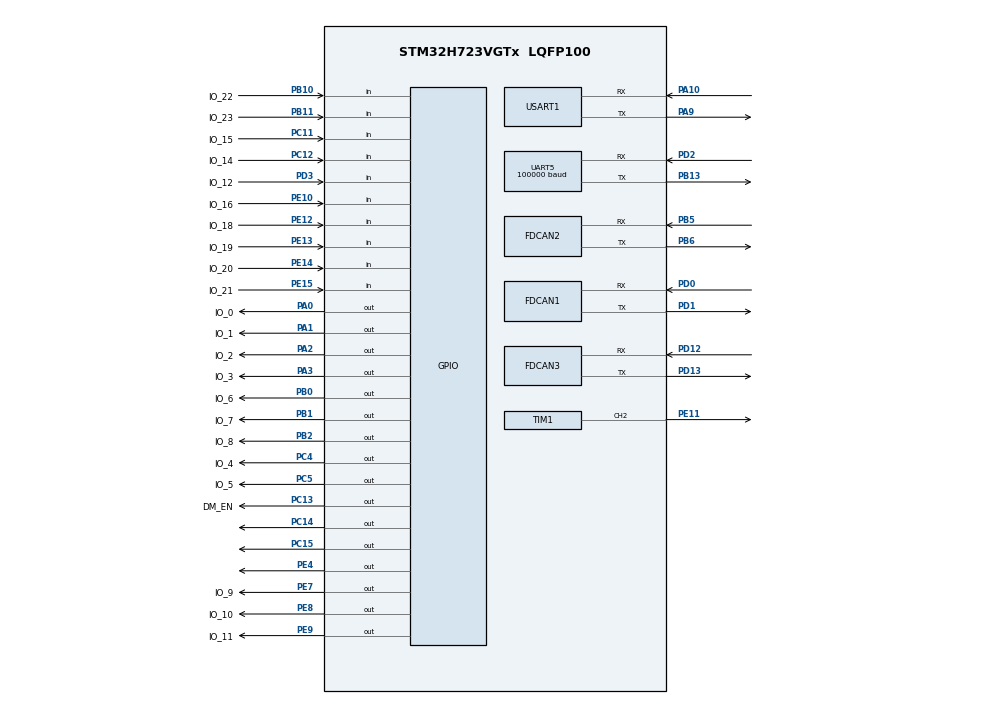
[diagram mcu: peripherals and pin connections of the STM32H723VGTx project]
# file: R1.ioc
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CORTEX_M7.MPU_Control=__NULL
CORTEX_M7.default_mode_Activation=1
Dma.Request0=TIM1_CH2
Dma.Request1=UART5_RX
Dma.Request2=USART1_RX
Dma.Request3=USART1_TX
Dma.TIM1_CH2.0.Direction=DMA_MEMORY_TO_PERIPH
Dma.TIM1_CH2.0.EventEnable=DISABLE
Dma.TIM1_CH2.0.FIFOMode=DMA_FIFOMODE_DISABLE
Dma.TIM1_CH2.0.Instance=DMA1_Stream6
Dma.TIM1_CH2.0.MemDataAlignment=DMA_MDATAALIGN_HALFWORD
Dma.TIM1_CH2.0.MemInc=DMA_MINC_ENABLE
Dma.TIM1_CH2.0.Mode=DMA_NORMAL
Dma.TIM1_CH2.0.PeriphDataAlignment=DMA_PDATAALIGN_HALFWORD
Dma.TIM1_CH2.0.PeriphInc=DMA_PINC_DISABLE
Dma.TIM1_CH2.0.Polarity=HAL_DMAMUX_REQ_GEN_RISING
Dma.TIM1_CH2.0.Priority=DMA_PRIORITY_VERY_HIGH
Dma.TIM1_CH2.0.RequestNumber=1
Dma.TIM1_CH2.0.SignalID=NONE
Dma.TIM1_CH2.0.SyncEnable=DISABLE
Dma.TIM1_CH2.0.SyncPolarity=HAL_DMAMUX_SYNC_NO_EVENT
Dma.TIM1_CH2.0.SyncRequestNumber=1
Dma.TIM1_CH2.0.SyncSignalID=NONE
Dma.UART5_RX.1.Direction=DMA_PERIPH_TO_MEMORY
Dma.UART5_RX.1.EventEnable=DISABLE
Dma.UART5_RX.1.FIFOMode=DMA_FIFOMODE_DISABLE
Dma.UART5_RX.1.Instance=DMA1_Stream0
Dma.UART5_RX.1.MemDataAlignment=DMA_MDATAALIGN_BYTE
Dma.UART5_RX.1.MemInc=DMA_MINC_ENABLE
Dma.UART5_RX.1.Mode=DMA_NORMAL
Dma.UART5_RX.1.PeriphDataAlignment=DMA_PDATAALIGN_BYTE
Dma.UART5_RX.1.PeriphInc=DMA_PINC_DISABLE
Dma.UART5_RX.1.Polarity=HAL_DMAMUX_REQ_GEN_RISING
Dma.UART5_RX.1.Priority=DMA_PRIORITY_HIGH
Dma.UART5_RX.1.RequestNumber=1
Dma.UART5_RX.1.SignalID=NONE
Dma.UART5_RX.1.SyncEnable=DISABLE
Dma.UART5_RX.1.SyncPolarity=HAL_DMAMUX_SYNC_NO_EVENT
Dma.UART5_RX.1.SyncRequestNumber=1
Dma.UART5_RX.1.SyncSignalID=NONE
Dma.USART1_RX.2.Direction=DMA_PERIPH_TO_MEMORY
Dma.USART1_RX.2.EventEnable=DISABLE
Dma.USART1_RX.2.FIFOMode=DMA_FIFOMODE_DISABLE
Dma.USART1_RX.2.Instance=DMA1_Stream1
Dma.USART1_RX.2.MemDataAlignment=DMA_MDATAALIGN_BYTE
Dma.USART1_RX.2.MemInc=DMA_MINC_ENABLE
Dma.USART1_RX.2.Mode=DMA_NORMAL
Dma.USART1_RX.2.PeriphDataAlignment=DMA_PDATAALIGN_BYTE
Dma.USART1_RX.2.PeriphInc=DMA_PINC_DISABLE
Dma.USART1_RX.2.Polarity=HAL_DMAMUX_REQ_GEN_RISING
Dma.USART1_RX.2.Priority=DMA_PRIORITY_MEDIUM
Dma.USART1_RX.2.RequestNumber=1
Dma.USART1_RX.2.SignalID=NONE
Dma.USART1_RX.2.SyncEnable=DISABLE
Dma.USART1_RX.2.SyncPolarity=HAL_DMAMUX_SYNC_NO_EVENT
Dma.USART1_RX.2.SyncRequestNumber=1
Dma.USART1_RX.2.SyncSignalID=NONE
Dma.USART1_TX.3.Direction=DMA_MEMORY_TO_PERIPH
Dma.USART1_TX.3.EventEnable=DISABLE
Dma.USART1_TX.3.FIFOMode=DMA_FIFOMODE_DISABLE
Dma.USART1_TX.3.Instance=DMA1_Stream2
Dma.USART1_TX.3.MemDataAlignment=DMA_MDATAALIGN_BYTE
Dma.USART1_TX.3.MemInc=DMA_MINC_ENABLE
Dma.USART1_TX.3.Mode=DMA_NORMAL
Dma.USART1_TX.3.PeriphDataAlignment=DMA_PDATAALIGN_BYTE
Dma.USART1_TX.3.PeriphInc=DMA_PINC_DISABLE
Dma.USART1_TX.3.Polarity=HAL_DMAMUX_REQ_GEN_RISING
Dma.USART1_TX.3.Priority=DMA_PRIORITY_MEDIUM
Dma.USART1_TX.3.RequestNumber=1
Dma.USART1_TX.3.SignalID=NONE
Dma.USART1_TX.3.SyncEnable=DISABLE
Dma.USART1_TX.3.SyncPolarity=HAL_DMAMUX_SYNC_NO_EVENT
Dma.USART1_TX.3.SyncRequestNumber=1
Dma.USART1_TX.3.SyncSignalID=NONE
FDCAN1.AutoRetransmission=ENABLE
FDCAN1.CalculateBaudRateNominal=1000000
FDCAN1.CalculateTimeBitNominal=1000
FDCAN1.CalculateTimeQuantumNominal=25.0
FDCAN1.DataPrescaler=3
FDCAN1.DataSyncJumpWidth=10
FDCAN1.DataTimeSeg1=29
FDCAN1.DataTimeSeg2=5
FDCAN1.NominalPrescaler=3
FDCAN1.NominalSyncJumpWidth=10
FDCAN1.NominalTimeSeg1=29
FDCAN1.NominalTimeSeg2=10
FDCAN1.RxFifo0ElmtsNbr=4
FDCAN1.StdFiltersNbr=1
FDCAN1.TxBuffersNbr=28
FDCAN1.TxFifoQueueElmtsNbr=4
FDCAN2.AutoRetransmission=ENABLE
FDCAN2.CalculateBaudRateNominal=1000000
FDCAN2.CalculateTimeBitNominal=1000
FDCAN2.CalculateTimeQuantumNominal=25.0
FDCAN2.DataPrescaler=3
FDCAN2.DataSyncJumpWidth=10
FDCAN2.DataTimeSeg1=29
FDCAN2.DataTimeSeg2=5
FDCAN2.MessageRAMOffset=852
FDCAN2.NominalPrescaler=3
FDCAN2.NominalSyncJumpWidth=10
FDCAN2.NominalTimeSeg1=29
FDCAN2.NominalTimeSeg2=10
FDCAN2.RxFifo0ElmtsNbr=4
FDCAN2.StdFiltersNbr=1
FDCAN2.TxBuffersNbr=28
FDCAN2.TxFifoQueueElmtsNbr=4
FDCAN3.AutoRetransmission=ENABLE
FDCAN3.CalculateBaudRateNominal=500000
FDCAN3.CalculateTimeBitNominal=2000
FDCAN3.CalculateTimeQuantumNominal=25.0
FDCAN3.MessageRAMOffset=1024
FDCAN3.NominalPrescaler=3
FDCAN3.NominalSyncJumpWidth=10
FDCAN3.NominalTimeSeg1=69
FDCAN3.NominalTimeSeg2=10
FDCAN3.RxFifo0ElmtsNbr=4
FDCAN3.TxBuffersNbr=32
FREERTOS.BinarySemaphores01=Joy_Data,Dynamic,NULL,Depleted;Gyro_Data,Dynamic,NULL,Depleted;Radar_Data,Dynamic,NULL,Depleted;DT35_Data,Dynamic,NULL,Depleted;Chassis_Low_Speed,Dynamic,NULL,Depleted;ready_connect,Dynamic,NULL,Depleted;transform_weapon,Dynamic,NULL,Depleted;recycle_arm,Dynamic,NULL,Depleted;ready_capture,Dynamic,NULL,Depleted;ready_suction,Dynamic,NULL,Depleted;start_capture,Dynamic,NULL,Depleted;start_suction,Dynamic,NULL,Depleted;start_center,Dynamic,NULL,Depleted;Take_block,Dynamic,NULL,Depleted;close_sucker,Dynamic,NULL,Depleted;transmit_block,Dynamic,NULL,Depleted;place_block,Dynamic,NULL,Depleted;Laser_L_Data,Dynamic,NULL,Depleted;Laser_R_Data,Dynamic,NULL,Depleted;Air_Data,Dynamic,NULL,Depleted;arm_init,Dynamic,NULL,Depleted;Close_R_Sucker,Dynamic,NULL,Depleted
FREERTOS.Queues01=Handle_Data_ToChassis,1,Handle_Data,0,Dynamic,NULL,NULL;Handle_Data_ToUpper,1,Handle_Data,0,Dynamic,NULL,NULL;Chassis_To_Can,1,Chassis_Motor,0,Dynamic,NULL,NULL
FREERTOS.Tasks01=print,15,256,App_print,As weak,NULL,Dynamic,NULL,NULL;FDCAN,24,512,App_FDCAN,As external,NULL,Dynamic,NULL,NULL
Mcu.Family=STM32H7
Mcu.Name=STM32H723VGTx
Mcu.Package=LQFP100
NVIC.DMA1_Stream0_IRQn=true\:5\:0\:false\:false\:true\:true\:false\:true\:true
NVIC.DMA1_Stream1_IRQn=true\:5\:0\:false\:false\:true\:true\:false\:true\:true
NVIC.DMA1_Stream2_IRQn=true\:5\:0\:false\:false\:true\:true\:false\:true\:true
NVIC.DMA1_Stream6_IRQn=true\:5\:0\:false\:false\:true\:true\:false\:true\:true
NVIC.FDCAN1_IT0_IRQn=true\:5\:0\:false\:false\:true\:true\:true\:true\:true
NVIC.FDCAN1_IT1_IRQn=true\:5\:0\:false\:false\:true\:true\:true\:true\:true
NVIC.FDCAN2_IT0_IRQn=true\:5\:0\:false\:false\:true\:true\:true\:true\:true
NVIC.FDCAN2_IT1_IRQn=true\:5\:0\:false\:false\:true\:true\:true\:true\:true
NVIC.FDCAN3_IT0_IRQn=true\:5\:0\:false\:false\:true\:true\:true\:true\:true
NVIC.PriorityGroup=NVIC_PRIORITYGROUP_4
NVIC.TIM4_IRQn=true\:5\:0\:false\:false\:true\:true\:true\:true\:true
NVIC.TIM5_IRQn=true\:5\:0\:false\:false\:true\:true\:true\:true\:true
NVIC.TIM6_DAC_IRQn=true\:15\:0\:false\:false\:true\:false\:false\:true\:true
NVIC.TimeBase=TIM6_DAC_IRQn
NVIC.TimeBaseIP=TIM6
NVIC.UART5_IRQn=true\:5\:0\:false\:false\:true\:true\:true\:true\:true
PA0.GPIO_Label=IO_0
PA0.GPIO_PuPd=GPIO_PULLUP
PA0.PinState=GPIO_PIN_SET
PA0.Signal=GPIO_Output
PA1.GPIO_Label=IO_1
PA1.GPIO_PuPd=GPIO_PULLUP
PA1.Signal=GPIO_Output
PA10.Mode=Asynchronous
PA10.Signal=USART1_RX
PA13(JTMS/SWDIO).Mode=Serial_Wire
PA13(JTMS/SWDIO).Signal=DEBUG_JTMS-SWDIO
PA14(JTCK/SWCLK).Mode=Serial_Wire
PA14(JTCK/SWCLK).Signal=DEBUG_JTCK-SWCLK
PA2.GPIO_Label=IO_2
PA2.GPIO_PuPd=GPIO_PULLUP
PA2.Signal=GPIO_Output
PA3.GPIO_Label=IO_3
PA3.GPIO_PuPd=GPIO_PULLUP
PA3.Signal=GPIO_Output
PA9.Mode=Asynchronous
PA9.Signal=USART1_TX
PB0.GPIO_Label=IO_6
PB0.GPIO_PuPd=GPIO_PULLUP
PB0.Signal=GPIO_Output
PB1.GPIO_Label=IO_7
PB1.GPIO_PuPd=GPIO_PULLUP
PB1.Signal=GPIO_Output
PB10.GPIO_Label=IO_22
PB10.GPIO_PuPd=GPIO_PULLDOWN
PB10.Signal=GPIO_Input
PB11.GPIO_Label=IO_23
PB11.GPIO_PuPd=GPIO_PULLDOWN
PB11.Signal=GPIO_Input
PB13.Mode=Asynchronous
PB13.Signal=UART5_TX
PB2.GPIO_Label=IO_8
PB2.GPIO_PuPd=GPIO_PULLUP
PB2.Signal=GPIO_Output
PB3(JTDO/TRACESWO).Signal=UART7_RX
PB4(NJTRST).Signal=UART7_TX
PB5.Mode=FDCAN_Activate
PB5.Signal=FDCAN2_RX
PB6.Mode=FDCAN_Activate
PB6.Signal=FDCAN2_TX
PB8.Signal=UART4_RX
PB9.Signal=UART4_TX
PC11.GPIO_Label=IO_15
PC11.GPIO_PuPd=GPIO_PULLDOWN
PC11.Signal=GPIO_Input
PC12.GPIO_Label=IO_14
PC12.GPIO_PuPd=GPIO_PULLDOWN
PC12.Signal=GPIO_Input
PC13.GPIO_Label=DM_EN
PC13.GPIO_Speed=GPIO_SPEED_FREQ_LOW
PC13.PinState=GPIO_PIN_SET
PC13.Signal=GPIO_Output
PC14-OSC32_IN.PinState=GPIO_PIN_SET
PC14-OSC32_IN.Signal=GPIO_Output
PC15-OSC32_OUT.PinState=GPIO_PIN_SET
PC15-OSC32_OUT.Signal=GPIO_Output
PC4.GPIO_Label=IO_4
PC4.GPIO_PuPd=GPIO_PULLUP
PC4.Signal=GPIO_Output
PC5.GPIO_Label=IO_5
PC5.GPIO_PuPd=GPIO_PULLUP
PC5.Signal=GPIO_Output
PD0.Mode=FDCAN_Activate
PD0.Signal=FDCAN1_RX
PD1.Mode=FDCAN_Activate
PD1.Signal=FDCAN1_TX
PD12.Mode=FDCAN_Activate
PD12.Signal=FDCAN3_RX
PD13.Mode=FDCAN_Activate
PD13.Signal=FDCAN3_TX
PD14.Signal=UART9_RX
PD2.Mode=Asynchronous
PD2.Signal=UART5_RX
PD3.GPIO_Label=IO_12
PD3.GPIO_PuPd=GPIO_PULLDOWN
PD3.Signal=GPIO_Input
PD5.Signal=USART2_TX
PD6.Signal=USART2_RX
PE0.Signal=UART8_RX
PE10.GPIO_Label=IO_16
PE10.GPIO_PuPd=GPIO_PULLDOWN
PE10.Signal=GPIO_Input
PE11.Signal=S_TIM1_CH2
PE12.GPIO_Label=IO_18
PE12.GPIO_PuPd=GPIO_PULLDOWN
PE12.Signal=GPIO_Input
PE13.GPIO_Label=IO_19
PE13.GPIO_PuPd=GPIO_PULLDOWN
PE13.Signal=GPIO_Input
PE14.GPIO_Label=IO_20
PE14.GPIO_PuPd=GPIO_PULLDOWN
PE14.Signal=GPIO_Input
PE15.GPIO_Label=IO_21
PE15.GPIO_PuPd=GPIO_PULLDOWN
PE15.Signal=GPIO_Input
PE3.Signal=USART10_TX
PE4.GPIO_PuPd=GPIO_PULLUP
PE4.Signal=GPIO_Output
PE7.GPIO_Label=IO_9
PE7.GPIO_PuPd=GPIO_PULLUP
PE7.Signal=GPIO_Output
PE8.GPIO_Label=IO_10
PE8.GPIO_PuPd=GPIO_PULLUP
PE8.Signal=GPIO_Output
PE9.GPIO_Label=IO_11
PE9.GPIO_PuPd=GPIO_PULLUP
PE9.Signal=GPIO_Output
PH0-OSC_IN.Mode=HSE-External-Oscillator
PH0-OSC_IN.Signal=RCC_OSC_IN
PH1-OSC_OUT.Mode=HSE-External-Oscillator
PH1-OSC_OUT.Signal=RCC_OSC_OUT
ProjectManager.HeapSize=0x10000
ProjectManager.StackSize=0x4000
ProjectManager.TargetToolchain=MDK-ARM V5.32
RCC.ADCFreq_Value=100000000
RCC.APB1Freq_Value=120000000
RCC.APB2Freq_Value=120000000
RCC.APB3Freq_Value=120000000
RCC.APB4Freq_Value=120000000
RCC.CortexFreq_Value=480000000
RCC.D1PPRE=RCC_APB3_DIV2
RCC.D2PPRE1=RCC_APB1_DIV2
RCC.D2PPRE2=RCC_APB2_DIV2
RCC.D3PPRE=RCC_APB4_DIV2
RCC.DIVM1=2
RCC.DIVM2=12
RCC.DIVM3=24
RCC.DIVN1=40
RCC.DIVN2=100
RCC.DIVN3=160
RCC.DIVP1=1
RCC.DIVQ1=4
RCC.DIVQ2=4
RCC.HCLKFreq_Value=240000000
RCC.HPRE=RCC_HCLK_DIV2
RCC.HSE_VALUE=24000000
RCC.PLL2FRACN=0
RCC.PLL3FRACN=0
RCC.PLLFRACN=0
RCC.PLLSourceVirtual=RCC_PLLSOURCE_HSE
RCC.SYSCLKFreq_VALUE=480000000
RCC.SYSCLKSource=RCC_SYSCLKSOURCE_PLLCLK
RCC.USBFreq_Value=120000000
SH.S_TIM1_CH2.0=TIM1_CH2,PWM Generation2 CH2
STMicroelectronics.X-CUBE-ALGOBUILD.1.4.0.LibraryCcDSPOoLibraryJjDSPOoLibrary=true
TIM1.Channel-PWM\ Generation2\ CH2=TIM_CHANNEL_2
TIM1.Period=77
TIM1.Prescaler=3
TIM4.AutoReloadPreload=TIM_AUTORELOAD_PRELOAD_ENABLE
TIM4.Period=100-1
TIM4.Prescaler=2500 - 1
TIM5.AutoReloadPreload=TIM_AUTORELOAD_PRELOAD_ENABLE
TIM5.Period=100-1
TIM5.Prescaler=2500-1
UART5.BaudRate=100000
UART5.Parity=PARITY_EVEN
UART5.StopBits=UART_STOPBITS_2
UART5.WordLength=WORDLENGTH_9B
USART1.VirtualMode-Asynchronous=VM_ASYNC
USART1.WordLength=WORDLENGTH_8B
USART2.BaudRate=4000000
USART2.VirtualMode-Asynchronous=VM_ASYNC
USART2.WordLength=WORDLENGTH_8B
VP_FREERTOS_VS_CMSIS_V2.Mode=CMSIS_V2
VP_IWDG1_VS_IWDG.Mode=IWDG_Activate
VP_MEMORYMAP_VS_MEMORYMAP.Mode=CurAppReg
VP_STMicroelectronics.X-CUBE-ALGOBUILD_VS_DSPOoLibraryJjLibrary_1.4.0_1.4.0.Mode=DSPOoLibraryJjLibrary
VP_SYS_VS_tim6.Mode=TIM6
VP_TIM1_VS_ClockSourceINT.Mode=Internal
VP_TIM2_VS_ClockSourceINT.Mode=Internal
VP_TIM4_VS_ClockSourceINT.Mode=Internal
VP_TIM5_VS_ClockSourceINT.Mode=Internal
board=custom

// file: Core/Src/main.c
/* USER CODE BEGIN Header */
/**
  ******************************************************************************
  * @file           : main.c
  * @brief          : Main program body
  ******************************************************************************
  * @attention
  *
  * Copyright (c) 2026 STMicroelectronics.
  * All rights reserved.
  *
  * This software is licensed under terms that can be found in the LICENSE file
  * in the root directory of this software component.
  * If no LICENSE file comes with this software, it is provided AS-IS.
  *
  ******************************************************************************
  */
/* USER CODE END Header */
#include "main.h"
#include "cmsis_os.h"
#include "dma.h"
#include "fdcan.h"
#include "iwdg.h"
#include "tim.h"
#include "usart.h"
#include "gpio.h"

/* USER CODE BEGIN Includes */
#include "go_control.h"

/* USER CODE END Includes */

void SystemClock_Config(void);
void MX_FREERTOS_Init(void);

int main(void)
{

  /* MCU Configuration--------------------------------------------------------*/

  /* Reset of all peripherals, Initializes the Flash interface and the Systick. */
  HAL_Init();

  /* Configure the system clock */
  SystemClock_Config();

  /* Initialize all configured peripherals */
  MX_GPIO_Init();
  MX_DMA_Init();
  MX_FDCAN1_Init();
  MX_FDCAN2_Init();
  MX_TIM4_Init();
  MX_TIM5_Init();
  MX_TIM1_Init();
  MX_FDCAN3_Init();
  MX_IWDG1_Init();
  MX_UART5_Init();
  MX_USART1_UART_Init();
  MX_USART2_UART_Init();
  MX_TIM2_Init();
  /* USER CODE BEGIN 2 */
  Chassis_C620_Init();
  Uart_Init();
  GO_App_Init();          /* 宇树 GO 电机：USART2(4Mbps) + PD4 方向脚，两台 ID 0/1 */
  /* USER CODE END 2 */

  /* Init scheduler */
  osKernelInitialize();  /* Call init function for freertos objects (in cmsis_os2.c) */
  MX_FREERTOS_Init();

  /* Start scheduler */
  osKernelStart();

  /* We should never get here as control is now taken by the scheduler */

  /* Infinite loop */
  while (1)
  {

  }
}

void SystemClock_Config(void)
{
  RCC_OscInitTypeDef RCC_OscInitStruct = {0};
  RCC_ClkInitTypeDef RCC_ClkInitStruct = {0};

  /** Supply configuration update enable
  */
  HAL_PWREx_ConfigSupply(PWR_LDO_SUPPLY);

  /** Configure the main internal regulator output voltage
  */
  __HAL_PWR_VOLTAGESCALING_CONFIG(PWR_REGULATOR_VOLTAGE_SCALE0);

  while(!__HAL_PWR_GET_FLAG(PWR_FLAG_VOSRDY)) {}

  /** Initializes the RCC Oscillators according to the specified parameters
  * in the RCC_OscInitTypeDef structure.
  */
  RCC_OscInitStruct.OscillatorType = RCC_OSCILLATORTYPE_LSI|RCC_OSCILLATORTYPE_HSE;
  RCC_OscInitStruct.HSEState = RCC_HSE_ON;
  RCC_OscInitStruct.LSIState = RCC_LSI_ON;
  RCC_OscInitStruct.PLL.PLLState = RCC_PLL_ON;
  RCC_OscInitStruct.PLL.PLLSource = RCC_PLLSOURCE_HSE;
  RCC_OscInitStruct.PLL.PLLM = 2;
  RCC_OscInitStruct.PLL.PLLN = 40;
  RCC_OscInitStruct.PLL.PLLP = 1;
  RCC_OscInitStruct.PLL.PLLQ = 4;
  RCC_OscInitStruct.PLL.PLLR = 2;
  RCC_OscInitStruct.PLL.PLLRGE = RCC_PLL1VCIRANGE_3;
  RCC_OscInitStruct.PLL.PLLVCOSEL = RCC_PLL1VCOWIDE;
  RCC_OscInitStruct.PLL.PLLFRACN = 0;
  if (HAL_RCC_OscConfig(&RCC_OscInitStruct) != HAL_OK)
  {
    Error_Handler();
  }

  /** Initializes the CPU, AHB and APB buses clocks
  */
  RCC_ClkInitStruct.ClockType = RCC_CLOCKTYPE_HCLK|RCC_CLOCKTYPE_SYSCLK
                              |RCC_CLOCKTYPE_PCLK1|RCC_CLOCKTYPE_PCLK2
                              |RCC_CLOCKTYPE_D3PCLK1|RCC_CLOCKTYPE_D1PCLK1;
  RCC_ClkInitStruct.SYSCLKSource = RCC_SYSCLKSOURCE_PLLCLK;
  RCC_ClkInitStruct.SYSCLKDivider = RCC_SYSCLK_DIV1;
  RCC_ClkInitStruct.AHBCLKDivider = RCC_HCLK_DIV2;
  RCC_ClkInitStruct.APB3CLKDivider = RCC_APB3_DIV2;
  RCC_ClkInitStruct.APB1CLKDivider = RCC_APB1_DIV2;
  RCC_ClkInitStruct.APB2CLKDivider = RCC_APB2_DIV2;
  RCC_ClkInitStruct.APB4CLKDivider = RCC_APB4_DIV2;

  if (HAL_RCC_ClockConfig(&RCC_ClkInitStruct, FLASH_LATENCY_3) != HAL_OK)
  {
    Error_Handler();
  }
}

void HAL_TIM_PeriodElapsedCallback(TIM_HandleTypeDef *htim)
{
  if (htim->Instance == TIM6)
  {
    HAL_IncTick();
  }
}

void Error_Handler(void)
{
  __disable_irq();
  while (1)
  {
  }
}

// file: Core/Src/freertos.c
/* USER CODE BEGIN Header */
/**
  ******************************************************************************
  * File Name          : freertos.c
  * Description        : Code for freertos applications
  ******************************************************************************
  * @attention
  *
  * Copyright (c) 2026 STMicroelectronics.
  * All rights reserved.
  *
  * This software is licensed under terms that can be found in the LICENSE file
  * in the root directory of this software component.
  * If no LICENSE file comes with this software, it is provided AS-IS.
  *
  ******************************************************************************
  */
/* USER CODE END Header */

#include "FreeRTOS.h"
#include "task.h"
#include "main.h"
#include "cmsis_os.h"

/* USER CODE BEGIN Includes */
#include "chassis.h"
#include "handle_rev.h"

/* USER CODE END Includes */

/* Definitions for print */
osThreadId_t printHandle;
const osThreadAttr_t print_attributes = {
  .name = "print",
  .stack_size = 256 * 4,
  .priority = (osPriority_t) osPriorityLow7,
};
/* Definitions for FDCAN */
osThreadId_t FDCANHandle;
const osThreadAttr_t FDCAN_attributes = {
  .name = "FDCAN",
  .stack_size = 512 * 4,
  .priority = (osPriority_t) osPriorityNormal,
};
/* Definitions for DM_J4310 */
osThreadId_t DM_J4310Handle;
const osThreadAttr_t DM_J4310_attributes = {
  .name = "DM_J4310",
  .stack_size = 256 * 4,
  .priority = (osPriority_t) osPriorityNormal,
};
/* Definitions for Unitree GO */
osThreadId_t GO_JointHandle;
const osThreadAttr_t GO_Joint_attributes = {
  .name = "GO_Joint",
  .stack_size = 384 * 4,
  .priority = (osPriority_t) osPriorityNormal,
};
/* Definitions for Handle_Data_ToChassis */
osMessageQueueId_t Handle_Data_ToChassisHandle;
const osMessageQueueAttr_t Handle_Data_ToChassis_attributes = {
  .name = "Handle_Data_ToChassis"
};
/* Definitions for Handle_Data_ToUpper */
osMessageQueueId_t Handle_Data_ToUpperHandle;
const osMessageQueueAttr_t Handle_Data_ToUpper_attributes = {
  .name = "Handle_Data_ToUpper"
};
/* Definitions for Chassis_To_Can */
osMessageQueueId_t Chassis_To_CanHandle;
const osMessageQueueAttr_t Chassis_To_Can_attributes = {
  .name = "Chassis_To_Can"
};
/* Definitions for Joy_Data */
osSemaphoreId_t Joy_DataHandle;
const osSemaphoreAttr_t Joy_Data_attributes = {
  .name = "Joy_Data"
};
/* Definitions for Gyro_Data */
osSemaphoreId_t Gyro_DataHandle;
const osSemaphoreAttr_t Gyro_Data_attributes = {
  .name = "Gyro_Data"
};
/* Definitions for Radar_Data */
osSemaphoreId_t Radar_DataHandle;
const osSemaphoreAttr_t Radar_Data_attributes = {
  .name = "Radar_Data"
};
/* Definitions for DT35_Data */
osSemaphoreId_t DT35_DataHandle;
const osSemaphoreAttr_t DT35_Data_attributes = {
  .name = "DT35_Data"
};
/* Definitions for Chassis_Low_Speed */
osSemaphoreId_t Chassis_Low_SpeedHandle;
const osSemaphoreAttr_t Chassis_Low_Speed_attributes = {
  .name = "Chassis_Low_Speed"
};
/* Definitions for ready_connect */
osSemaphoreId_t ready_connectHandle;
const osSemaphoreAttr_t ready_connect_attributes = {
  .name = "ready_connect"
};
/* Definitions for transform_weapon */
osSemaphoreId_t transform_weaponHandle;
const osSemaphoreAttr_t transform_weapon_attributes = {
  .name = "transform_weapon"
};
/* Definitions for recycle_arm */
osSemaphoreId_t recycle_armHandle;
const osSemaphoreAttr_t recycle_arm_attributes = {
  .name = "recycle_arm"
};
/* Definitions for ready_capture */
osSemaphoreId_t ready_captureHandle;
const osSemaphoreAttr_t ready_capture_attributes = {
  .name = "ready_capture"
};
/* Definitions for ready_suction */
osSemaphoreId_t ready_suctionHandle;
const osSemaphoreAttr_t ready_suction_attributes = {
  .name = "ready_suction"
};
/* Definitions for start_capture */
osSemaphoreId_t start_captureHandle;
const osSemaphoreAttr_t start_capture_attributes = {
  .name = "start_capture"
};
/* Definitions for start_suction */
osSemaphoreId_t start_suctionHandle;
const osSemaphoreAttr_t start_suction_attributes = {
  .name = "start_suction"
};
/* Definitions for start_center */
osSemaphoreId_t start_centerHandle;
const osSemaphoreAttr_t start_center_attributes = {
  .name = "start_center"
};
/* Definitions for Take_block */
osSemaphoreId_t Take_blockHandle;
const osSemaphoreAttr_t Take_block_attributes = {
  .name = "Take_block"
};
/* Definitions for close_sucker */
osSemaphoreId_t close_suckerHandle;
const osSemaphoreAttr_t close_sucker_attributes = {
  .name = "close_sucker"
};
/* Definitions for transmit_block */
osSemaphoreId_t transmit_blockHandle;
const osSemaphoreAttr_t transmit_block_attributes = {
  .name = "transmit_block"
};
/* Definitions for place_block */
osSemaphoreId_t place_blockHandle;
const osSemaphoreAttr_t place_block_attributes = {
  .name = "place_block"
};
/* Definitions for Laser_L_Data */
osSemaphoreId_t Laser_L_DataHandle;
const osSemaphoreAttr_t Laser_L_Data_attributes = {
  .name = "Laser_L_Data"
};
/* Definitions for Laser_R_Data */
osSemaphoreId_t Laser_R_DataHandle;
const osSemaphoreAttr_t Laser_R_Data_attributes = {
  .name = "Laser_R_Data"
};
/* Definitions for Air_Data */
osSemaphoreId_t Air_DataHandle;
const osSemaphoreAttr_t Air_Data_attributes = {
  .name = "Air_Data"
};
/* Definitions for arm_init */
osSemaphoreId_t arm_initHandle;
const osSemaphoreAttr_t arm_init_attributes = {
  .name = "arm_init"
};
/* Definitions for Close_R_Sucker */
osSemaphoreId_t Close_R_SuckerHandle;
const osSemaphoreAttr_t Close_R_Sucker_attributes = {
  .name = "Close_R_Sucker"
};

/* USER CODE BEGIN FunctionPrototypes */
void App_SBUS_Chassis(void *argument);
void DM_J4310_Task(void *argument);
void GO_Task(void *argument);
/* USER CODE END FunctionPrototypes */

void App_print(void *argument);
extern void App_FDCAN(void *argument);

void MX_FREERTOS_Init(void); /* (MISRA C 2004 rule 8.1) */

void MX_FREERTOS_Init(void) {

  /* Create the semaphores(s) */
  /* creation of Joy_Data */
  Joy_DataHandle = osSemaphoreNew(1, 0, &Joy_Data_attributes);

  /* creation of Gyro_Data */
  Gyro_DataHandle = osSemaphoreNew(1, 0, &Gyro_Data_attributes);

  /* creation of Radar_Data */
  Radar_DataHandle = osSemaphoreNew(1, 0, &Radar_Data_attributes);

  /* creation of DT35_Data */
  DT35_DataHandle = osSemaphoreNew(1, 0, &DT35_Data_attributes);

  /* creation of Chassis_Low_Speed */
  Chassis_Low_SpeedHandle = osSemaphoreNew(1, 0, &Chassis_Low_Speed_attributes);

  /* creation of ready_connect */
  ready_connectHandle = osSemaphoreNew(1, 0, &ready_connect_attributes);

  /* creation of transform_weapon */
  transform_weaponHandle = osSemaphoreNew(1, 0, &transform_weapon_attributes);

  /* creation of recycle_arm */
  recycle_armHandle = osSemaphoreNew(1, 0, &recycle_arm_attributes);

  /* creation of ready_capture */
  ready_captureHandle = osSemaphoreNew(1, 0, &ready_capture_attributes);

  /* creation of ready_suction */
  ready_suctionHandle = osSemaphoreNew(1, 0, &ready_suction_attributes);

  /* creation of start_capture */
  start_captureHandle = osSemaphoreNew(1, 0, &start_capture_attributes);

  /* creation of start_suction */
  start_suctionHandle = osSemaphoreNew(1, 0, &start_suction_attributes);

  /* creation of start_center */
  start_centerHandle = osSemaphoreNew(1, 0, &start_center_attributes);

  /* creation of Take_block */
  Take_blockHandle = osSemaphoreNew(1, 0, &Take_block_attributes);

  /* creation of close_sucker */
  close_suckerHandle = osSemaphoreNew(1, 0, &close_sucker_attributes);

  /* creation of transmit_block */
  transmit_blockHandle = osSemaphoreNew(1, 0, &transmit_block_attributes);

  /* creation of place_block */
  place_blockHandle = osSemaphoreNew(1, 0, &place_block_attributes);

  /* creation of Laser_L_Data */
  Laser_L_DataHandle = osSemaphoreNew(1, 0, &Laser_L_Data_attributes);

  /* creation of Laser_R_Data */
  Laser_R_DataHandle = osSemaphoreNew(1, 0, &Laser_R_Data_attributes);

  /* creation of Air_Data */
  Air_DataHandle = osSemaphoreNew(1, 0, &Air_Data_attributes);

  /* creation of arm_init */
  arm_initHandle = osSemaphoreNew(1, 0, &arm_init_attributes);

  /* creation of Close_R_Sucker */
  Close_R_SuckerHandle = osSemaphoreNew(1, 0, &Close_R_Sucker_attributes);

  /* Create the queue(s) */
  /* creation of Handle_Data_ToChassis */
  Handle_Data_ToChassisHandle = osMessageQueueNew (1, sizeof(Handle_Data), &Handle_Data_ToChassis_attributes);

  /* creation of Handle_Data_ToUpper */
  Handle_Data_ToUpperHandle = osMessageQueueNew (1, sizeof(Handle_Data), &Handle_Data_ToUpper_attributes);

  /* creation of Chassis_To_Can */
  Chassis_To_CanHandle = osMessageQueueNew (1, sizeof(Chassis_Motor), &Chassis_To_Can_attributes);

  /* Create the thread(s) */
  /* creation of print */
  printHandle = osThreadNew(App_print, NULL, &print_attributes);

  /* creation of FDCAN */
  FDCANHandle = osThreadNew(App_FDCAN, NULL, &FDCAN_attributes);

  /* USER CODE BEGIN RTOS_THREADS */
  /* add threads, ... */
  osThreadNew(App_SBUS_Chassis, NULL, &FDCAN_attributes);
  DM_J4310Handle = osThreadNew(DM_J4310_Task, NULL, &DM_J4310_attributes);
  GO_JointHandle = osThreadNew(GO_Task, NULL, &GO_Joint_attributes);
  /* USER CODE END RTOS_THREADS */

}

__weak void App_print(void *argument)
{
  for(;;)
  {
    osDelay(1);
  }
}
